AUTOSAR XML (schema 4-1-1)
package /ARRoot
  composition sw component type aComposition
    component aComponentPrototype: type=aComponentType
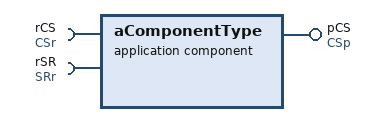
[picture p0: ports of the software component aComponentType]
  application sw component type aComponentType
    require port rCS: required-interface=CSr
    require port rSR: required-interface=SRr
    provide port pCS: provided-interface=CSp
  sender receiver interface SRr
  client server interface CSr
  client server interface CSp
    operation anOperation: possible-error=anError
    error anError: error-code=255
